# ET6801 register map
Vendor: ETMCU Inc.; File version: v0.0.1
CPU: CM7 r2p1, little endian, MPU, FPU, I-cache, D-cache, ITCM, DTCM, 4 interrupt priority bits
Registers are 32-bit, read-write, reset 0x0 unless marked. A register's access mark holds for its fields unless they carry their own. Offsets are from the block's base; [hi:lo] are bit positions; lines under a group give offsets from that group; {n}, {i} and the like mark numbered series.

## XBAR — Provide an overview of the purpose and functionality of the peripheral: xbar
Base 0x40020000
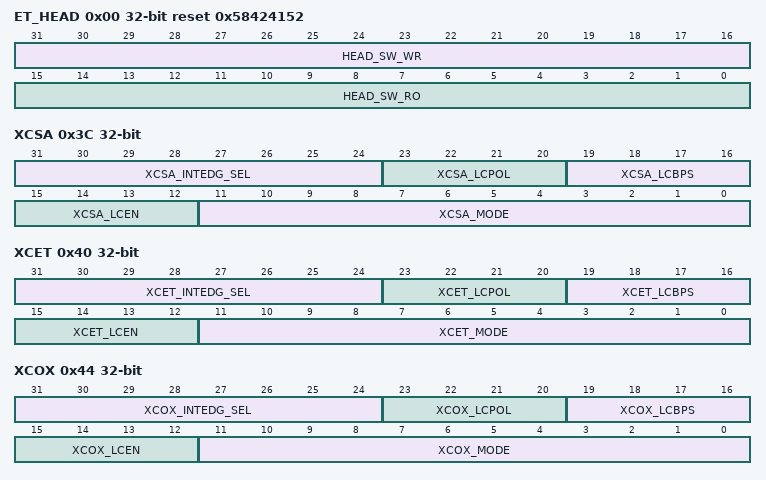
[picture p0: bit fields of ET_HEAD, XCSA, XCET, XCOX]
0x00 ET_HEAD reset 0x58424152
  [31:16] HEAD_SW_WR — 软件测试读写寄存器，硬件无访问
  [15:0] HEAD_SW_RO ro — 软件只读上报寄存器，硬件无访问，XBAR的ASICII 码表示
0x04 KEY
  [15:0] XBAR_KEY — XBAR配置key值，仅当配置为0x5a5a时可配置相关寄存器
0x08 FAULT_EN reset 0x7FFFFF
  [22:0] FAULT_EN — XBAR FAULT输入使能 0：对应fault不使能 1：对应fault使能
{0xC+8i} STM{i}ERG0_EN reset 0x7FFFFF (i=0..5)
  [22:0] STM{i}_ERGTRIG_0EN — STM{i}紧急触发源0使能 0：对应触发源不使能 1：对应触发源使能
{0x10+8i} STM{i}ERG1_EN reset 0x7FFFFF (i=0..5)
  [22:0] STM{i}_ERGTRIG_1EN — STM{i}紧急触发源1使能 0：对应触发源不使能 1：对应触发源使能
0x3C XCSA
  [31:24] XCSA_INTEDG_SEL — XBAR CLU2SAR 4个输出信号产生中断的沿类型选择 2'b01：上升沿 2'b10：下降沿 2'b11：上升沿和下降沿 其他：不取沿
  [23:20] XCSA_LCPOL — XBAR CLU2SAR输出4个bit对应的极性选择 0：不取反 1：取反
  [19:16] XCSA_LCBPS — XBAR CLU2SAR对应输出4个bit的CLU功能旁路使能，高有效，旁路后选择输出INPUTXBAR对应信号： CLU旁路输出bit0对应INPUTXBAR输出bit0 CLU旁路输出bit1对应INPUTXBAR输出bit4 CLU旁路输出bit2对应INPUTXBAR输出bit8 CLU旁路输出bit3对应INPUTXBAR输出bit12
  [15:12] XCSA_LCEN — XBAR CLU2SAR对应输出4个bit的输出使能： 0：输出低电平 1：输出高电平
  [11:0] XCSA_MODE — bit[2:0]：XBAR CLU2SAR输出bit0的8种逻辑选择 bit[5:3]：XBAR CLU2SAR输出bit1的8种逻辑选择 bit[8:6]：XBAR CLU2SAR输出bit2的8种逻辑选择 bit[11:9]：XBAR CLU2SAR输出bit3的8种逻辑选择
0x40 XCET
  [31:24] XCET_INTEDG_SEL — XBAR CLU2ETIMER 4个输出信号产生中断的沿类型选择 2'b01：上升沿 2'b10：下降沿 2'b11：上升沿和下降沿 其他：不取沿
  [23:20] XCET_LCPOL — XBAR CLU2ETIMER输出4个bit对应的极性选择 0：不取反 1：取反
  [19:16] XCET_LCBPS — XBAR CLU2ETIMER对应输出4个bit的CLU功能旁路使能，高有效，旁路后选择输出INPUTXBAR对应信号： CLU旁路输出bit0对应INPUTXBAR输出bit0 CLU旁路输出bit1对应INPUTXBAR输出bit4 CLU旁路输出bit2对应INPUTXBAR输出bit8 CLU旁路输出bit3对应INPUTXBAR输出bit12
  [15:12] XCET_LCEN — XBAR CLU2ETIMER对应输出4个bit的输出使能： 0：输出低电平 1：输出高电平
  [11:0] XCET_MODE — bit[2:0]：XBAR CLU2ETIMER输出bit0的8种逻辑选择 bit[5:3]：XBAR CLU2ETIMER输出bit1的8种逻辑选择 bit[8:6]：XBAR CLU2ETIMER输出bit2的8种逻辑选择 bit[11:9]：XBAR CLU2ETIMER输出bit3的8种逻辑选择
0x44 XCOX
  [31:24] XCOX_INTEDG_SEL — XBAR CLU2OUTXBAR 4个输出信号产生中断的沿类型选择 2'b01：上升沿 2'b10：下降沿 2'b11：上升沿和下降沿 其他：不取沿
  [23:20] XCOX_LCPOL — XBAR CLU2OUTXBAR输出4个bit对应的极性选择 0：不取反 1：取反
  [19:16] XCOX_LCBPS — XBAR CLU2OUTXBAR对应输出4个bit的CLU功能旁路使能，高有效，旁路后选择输出INPUTXBAR对应信号： CLU旁路输出bit0对应INPUTXBAR输出bit0 CLU旁路输出bit1对应INPUTXBAR输出bit4 CLU旁路输出bit2对应INPUTXBAR输出bit8 CLU旁路输出bit3对应INPUTXBAR输出bit12
  [15:12] XCOX_LCEN — XBAR CLU2OUTXBAR对应输出4个bit的输出使能： 0：输出低电平 1：输出高电平
  [11:0] XCOX_MODE — bit[2:0]：XBAR CLU2OUTXBAR输出bit0的8种逻辑选择 bit[5:3]：XBAR CLU2OUTXBAR输出bit1的8种逻辑选择 bit[8:6]：XBAR CLU2OUTXBAR输出bit2的8种逻辑选择 bit[11:9]：XBAR CLU2OUTXBAR输出bit3的8种逻辑选择
0x48 INXB_DSEL
  [31:0] INXB_DSEL — INPUTXBAR第0路到第15路输出信号处理选择： Bit[1:0]：INPUTXBAR第0路输出选择 2'd0：选择MUX后数据输出 2'd1：选择高电平锁存后数据输出 2'd2：选择上升沿输出 2'd3：选择下降沿输出 Bit[3:2]：INPUTXBAR第1路输出选择，选项同上 ... Bit[31:30]：INPUTXBAR第15路输出选择，选项同上
0x4C INXB_LATCLR
  [15:0] INXB_LAT_CLR — INPUTXBAR第0路到第15路输出信号锁存清除配置，自清0
0x50 INXB_OE
  [15:0] INXB_OE — INPUTXBAR第0路到第15路输出使能，高有效
0x54 INXB_OUTPOL
  [15:0] INXB_OUTPOL — INPUTXBAR第0路到第15路输出信号极性配置 0：不取反 1：取反
0x58 INXB_OUTDSEL reset 0xFFFF
  [15:0] INXB_OUTDSEL — INPUTXBAR第0路到第15路输出信号是否打拍手输出 0：不打拍 1：打拍
{0x5C+0xC*i} INXB_GRP[{i}] (i=0..15) group — CFG_INXB_GRP
  0x00 INXB_MUX0
    [31:0] INXB_15_0MUX — INPUTXBAR第N(0~15)路输出对应的第0到第15组MUX通道4选1配置
  0x04 INXB_MUX1
    [31:0] INXB_31_16MUX — INPUTXBAR第N(0~15)路输出对应的第16到第31组MUX通道4选1配置
  0x08 INXB_ENB
    [31:0] INXB_ENB — INPUTXBAR第N(0~15)路输出对应的第0到第31组MUX选择后信号ENB配置 0：不使能 1：使能
0x11C PFXB_DSEL
  [31:0] PFXB_DSEL — PWMXBAR第0路到第15路输出信号处理选择： Bit[1:0]：PWMXBAR第0路输出选择 2'd0：选择MUX后数据输出 2'd1：选择高电平锁存后数据输出 2'd2：选择上升沿输出 2'd3：选择下降沿输出 Bit[3:2]：PWMXBAR第1路输出选择，选项同上 ... Bit[21:20]：PWMXBAR第11路输出选择，选项同上
0x120 PFXB_LATCLR
  [15:0] PFXB_LAT_CLR — PWMXBAR第0路到第15路输出信号锁存清除配置，自清0
0x124 PFXB_OE
  [15:0] PFXB_OE — PWMXBAR第0路到第15路输出使能，高有效
0x128 PFXB_OUTPOL
  [15:0] PFXB_OUTPOL — PWMXBAR第0路到第15路输出信号极性配置 0：不取反 1：取反
0x12C PFXB_OUTDSEL reset 0xFFFF
  [15:0] PFXB_OUTDSEL — CLB_XBAR第0路到第15路输出信号是否打拍手输出 0：不打拍 1：打拍
{0x130+0x18*i} PFXB_GRP[{i}] (i=0..15) group — CFG_PFXB_GRP
  {0x0+4j} PFXB_MUX{j} (j=0..3)
    [31:0] PFXB_{16j+15}_{16j}MUX — PWMXBAR第N(0~11)路输出对应的第{16j}到第{16j+15}组MUX通道4选1配置
  0x10 PFXB_ENB0
    [31:0] PFXB_ENB — PWMXBAR第N(0~11)路输出对应的第0到第31组MUX选择后信号ENB配置 0：不使能 1：使能
  0x14 PFXB_ENB1
    [31:0] PFXB_ENB — PWMXBAR第N(0~11)路输出对应的第32到第63组MUX选择后信号ENB配置 0：不使能 1：使能
0x2B0 ETXB_DSEL
  [23:0] ETXB_DSEL — eTimer XBAR第0路到第11路输出信号处理选择： Bit[1:0]：eTimer XBAR第0路输出选择 2'd0：选择MUX后数据输出 2'd1：选择高电平锁存后数据输出 2'd2：选择上升沿输出 2'd3：选择下降沿输出 Bit[3:2]：eTimer XBAR第1路输出选择，选项同上 ... Bit[27:26]：eTimer XBAR第11路输出选择，选项同上
0x2B4 ETXB_LATCLR
  [11:0] ETXB_LAT_CLR — eTimer XBAR第0路到第11路输出信号锁存清除配置，自清0
0x2B8 ETXB_OE
  [11:0] ETXB_OE — eTimer XBAR第0路到第11路输出使能，高有效
0x2BC ETXB_OUTPOL
  [11:0] ETXB_OUTPOL — eTimer XBAR第0路到第11路输出信号极性配置 0：不取反 1：取反
0x2C0 ETXB_SW
  [11:0] ETXB_SW — eTimer XBAR软件配置的输入信号 Bit0：第0个软件通道配置 ... Bit13：第11个软件通道配置
0x2C4 ETXB_OUTDSEL reset 0xFFF
  [11:0] ETXB_OUTDSEL — eTimer_XBAR第0路到第11路输出信号是否打拍手输出 0：不打拍 1：打拍
{0x2C8+0xC*i} ETXB_GRP[{i}] (i=0..11) group — CFG_ETXB_GRP
  0x00 ETXB_MUX0
    [31:0] ETXB_15_0MUX — eTimer XBAR第N(0~13)路输出对应的第0到第15组MUX通道4选1配置
  0x04 ETXB_MUX1
    [31:0] ETXB_31_16MUX — eTimer XBAR第N(0~13)路输出对应的第16到第31组MUX通道4选1配置
  0x08 ETXB_ENB
    [31:0] ETXB_ENB — eTimer XBAR第N(0~13)路输出对应的第0到第31组MUX选择后信号ENB配置 0：不使能 1：使能
0x358 OPXB_DSEL
  [23:0] OPXB_DSEL — OUTPUTXBAR第0路到第11路输出信号处理选择： Bit[1:0]：OUTPUTXBAR第0路输出选择 根据 ：选择MUX异步处理后取上升沿沿展宽输出 Bit[3:2]：OUTPUTXBAR第1路输出选择，选项同上 ... Bit[27:26]：OUTPUTXBAR第11路输出选择，选项同上
0x35C OPXB_LATCLR
  [11:0] OPXB_LAT_CLR — OUTPUTXBAR第0路到第11路输出信号锁存清除配置，自清0
0x360 OPXB_OE
  [11:0] OPXB_OE — OUTPUTXBAR第0路到第11路输出使能，高有效
0x364 OPXB_OUTPOL
  [11:0] OPXB_OUTPOL — OUTPUTXBAR第0路到第11路输出信号极性配置 0：不取反 1：取反
0x368 OPXB_SW
  [11:0] OPXB_SW — OUTPUTXBAR软件配置的输入信号 Bit0：第0个软件通道配置 ... Bit13：第11个软件通道配置
0x36C OPXB_EXPEN
  [11:0] OPXB_EXP_EN — OUTPUTXBAR第0路到第11路电平扩展输出使能配置 根据 ：选择MUX异步处理后取上升沿沿展宽输出 展宽15个周期
0x370 OPXB_OEMOD
  [23:0] OPXB_OEMOD — bit[1:0]：OUTPUTXBAR第0路输出使能模式选择 2'd1：当选择信号中包含eTimer PWM信号时，对应输出管脚选择eTimer PWM oen作为输出使能，其他管脚固定输出有效 2'd2：固定输出三态 others：固定为输出有效 bit[3:2]：OUTPUTXBAR第1路输出使能模式选择 ... bit[27:26]：OUTPUTXBAR第11路输出使能模式选择
{0x374+0x18*i} OPXB_GRP[{i}] (i=0..11) group — CFG_OPXB_GRP
  {0x0+4j} OPXB_MUX{j} (j=0..3)
    [31:0] OPXB_{16j+15}_{16j}MUX — OUTPUTXBAR第N(0~11)路输出对应的第{16j}到第{16j+15}组MUX通道4选1配置
  0x10 OPXB_ENB0
    [31:0] OPXB_ENB — OUTPUTXBAR第N(0~11)路输出对应的第0到第31组MUX选择后信号ENB配置 0：不使能 1：使能
  0x14 OPXB_ENB1
    [31:0] OPXB_ENB — OUTPUTXBAR第N(0~11)路输出对应的第32到第63组MUX选择后信号ENB配置 0：不使能 1：使能
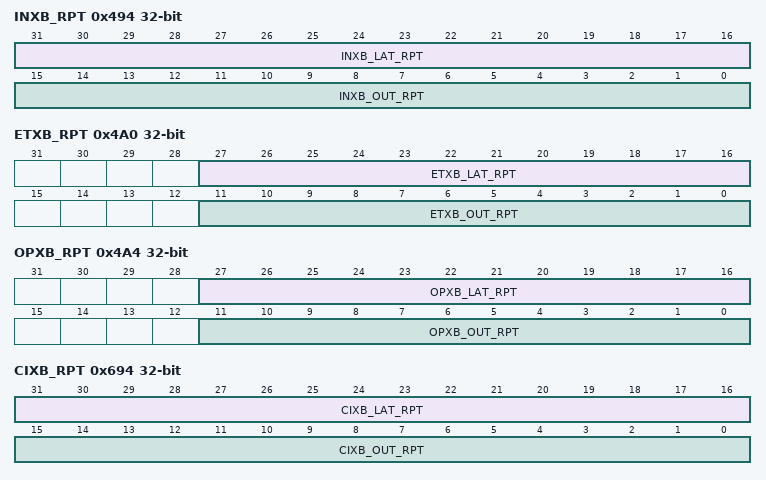
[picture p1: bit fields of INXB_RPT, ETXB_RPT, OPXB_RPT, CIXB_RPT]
0x494 INXB_RPT ro
  [31:16] INXB_LAT_RPT — INPUTXBAR锁存状态上报
  [15:0] INXB_OUT_RPT — INPUTXBAR实时输出状态上报
0x498 PFXB_RPT0 ro
  [15:0] PFXB_OUT_RPT — PWMXBAR实时输出状态上报
0x49C PFXB_RPT1 ro
  [15:0] PFXB_LAT_RPT — PWMXBAR锁存状态上报
0x4A0 ETXB_RPT ro
  [27:16] ETXB_LAT_RPT — eTimer XBAR锁存状态上报
  [11:0] ETXB_OUT_RPT — eTimer XBAR实时输出状态上报
0x4A4 OPXB_RPT ro
  [27:16] OPXB_LAT_RPT — OUTPUTXBAR锁存状态上报
  [11:0] OPXB_OUT_RPT — OUTPUTXBAR实时输出状态上报
0x4A8 CLU_INT_EN
  [11:0] CLU_INT_EN — 1表示使能CLU逻辑中断;0 取消使能 每一bit代表： bit[12]:xcox3 bit[11]:xcox2 bit[10]:xcox1 bit[9]:xcox0 bit[7]:xct3 bit[6]:xcet2 bit[5]:xcet1 bit[4]:xcet0 bit[3]:xcsa3 bit[2]:xcsa2 bit[1]:xcsa1 bit[0]:xcsa0
0x4AC CLU_INT_MASK
  [11:0] CLU_INT_MASK — 1表示屏蔽CLU逻辑中断;0 取消屏蔽 每一bit代表同CFG_CLU_INT_EN
0x4B0 CLU_INT_FORCE_IND
  [11:0] CLU_INT_FORCE_IND — 1表示强制产生相应的测试中断，硬件自清零 每一bit代表同CFG_CLU_INT_EN
0x4B4 CLU_INT_CLR
  [11:0] CLU_INT_CLR — 1表示清除相应的中断状态，硬件自清零 每一bit代表同CFG_CLU_INT_EN
0x4B8 CLU_INT_RAW_RPT ro
  [11:0] CLU_INT_RAW_RPT — 中断MASK前RAW 中断状态上报 每一bit代表同CFG_CLU_INT_EN
0x4BC CLU_INT_STATUS_RPT ro
  [11:0] CLU_INT_STATUS_RPT — 中断MASK后中断状态上报 每一bit代表同CFG_CLU_INT_EN
0x4C0 INXB_INT_EN
  [4:0] INXB_INT_EN — 1表示使能INXB逻辑中断;0 取消使能 每一bit代表： bit[4]:inxb_dout[15] bit[3]:inxb_dout[14] bit[2]:inxb_dout[13] bit[1]:inxb_dout[12]， bit[0]:inxb_dout[11],inputxbar输出的第11bit
0x4C4 INXB_INT_MASK
  [4:0] INXB_INT_MASK — 1表示屏蔽INXB逻辑中断;0 取消屏蔽 每一bit代表同CFG_INXB_INT_EN
0x4C8 INXB_INT_FORCE_IND
  [4:0] INXB_INT_FORCE_IND — 1表示强制产生相应的测试中断，硬件自清零 每一bit代表同CFG_INXB_INT_EN
0x4CC INXB_INT_CLR
  [4:0] INXB_INT_CLR — 1表示清除相应的中断状态，硬件自清零 每一bit代表同CFG_INXB_INT_EN
0x4D0 INXB_INT_RAW_RPT ro
  [4:0] INXB_INT_RAW_RPT — 中断MASK前RAW 中断状态上报 每一bit代表同CFG_INXB_INT_EN
0x4D4 INXB_INT_STATUS_RPT ro
  [4:0] INXB_INT_STATUS_RPT — 中断MASK后中断状态上报 每一bit代表同CFG_INXB_INT_EN
0x4D8 CIXB_DSEL
  [31:0] CIXB_DSEL — CLB_INPUTXBAR第0路到第15路输出信号处理选择： Bit[1:0]：CLB_INPUTXBAR第0路输出选择 2'd0：选择MUX后数据输出 2'd1：选择高电平锁存后数据输出 2'd2：选择上升沿输出 2'd3：选择下降沿输出 Bit[3:2]：CLB_INPUTXBAR第1路输出选择，选项同上 ... Bit[31:30]：CLB_INPUTXBAR第15路输出选择，选项同上
0x4DC CIXB_LATCLR
  [15:0] CIXB_LAT_CLR — CLB_INPUTXBAR第0路到第15路输出信号锁存清除配置，自清0
0x4E0 CIXB_OE
  [15:0] CIXB_OE — CLB_INPUTXBAR第0路到第15路输出使能，高有效
0x4E4 CIXB_OUTPOL
  [15:0] CIXB_OUTPOL — CLB_INPUTXBAR第0路到第15路输出信号极性配置 0：不取反 1：取反
0x4E8 CIXB_OUTDSEL reset 0xFFFF
  [15:0] CIXB_OUTDSEL — CLB_INPUTXBAR第0路到第15路输出信号是否打拍手输出 0：不打拍 1：打拍
{0x4EC+0xC*i} CIXB_GRP[{i}] (i=0..15) group — CFG_CIXB_GRP
  0x00 CIXB_MUX0
    [31:0] CIXB_15_0MUX — CLB_INPUTXBAR第N(0~15)路输出对应的第0到第15组MUX通道4选1配置
  0x04 CIXB_MUX1
    [31:0] CIXB_31_16MUX — CLB_INPUTXBAR第N(0~15)路输出对应的第16到第19组MUX通道4选1配置
  0x08 CIXB_ENB
    [31:0] CIXB_ENB — CLB_INPUTXBAR第N(0~15)路输出对应的第0到第31组MUX选择后信号ENB配置 0：不使能 1：使能
0x5AC CBXB_DSEL
  [15:0] CBXB_DSEL — CLB_XBAR第0路到第7路输出信号处理选择： Bit[1:0]：CLB_XBAR第0路输出选择 2'd0：选择MUX后数据输出 2'd1：选择高电平锁存后数据输出 2'd2：选择上升沿输出 2'd3：选择下降沿输出 Bit[3:2]：CLB_XBAR第1路输出选择，选项同上 ... Bit[15:14]：CLB_XBAR第7路输出选择，选项同上
0x5B0 CBXB_LATCLR
  [7:0] CBXB_LAT_CLR — CLB_XBAR第0路到第7路输出信号锁存清除配置，自清0
0x5B4 CBXB_OE
  [7:0] CBXB_OE — CLB_XBAR第0路到第7路输出使能，高有效
0x5B8 CBXB_OUTPOL
  [7:0] CBXB_OUTPOL — CLB_XBAR第0路到第7路输出信号极性配置 0：不取反 1：取反
0x5BC CBXB_OUTDSEL reset 0xFF
  [7:0] CBXB_OUTDSEL — CLB_XBAR第0路到第7路输出信号是否打拍手输出 0：不打拍 1：打拍
{0x5C0+0xC*i} CBXB_GRP[{i}] (i=0..7) group — CFG_CBXB_GRP
  0x00 CBXB_MUX0
    [31:0] CBXB_15_0MUX — CLB_XBAR第N(0~7)路输出对应的第0到第15组MUX通道4选1配置
  0x04 CBXB_MUX1
    [31:0] CBXB_31_16MUX — CLB_XBAR第N(0~7)路输出对应的第16到第31组MUX通道4选1配置
  0x08 CBXB_ENB
    [31:0] CBXB_ENB — CLB_XBAR第N(0~7)路输出对应的第0到第31组MUX选择后信号ENB配置 0：不使能 1：使能
0x620 COXB_DSEL
  [15:0] COXB_DSEL — OUTPUTXBAR第0路到第7路输出信号处理选择： Bit[1:0]：OUTPUTXBAR第0路输出选择 根据 ：选择MUX异步处理后取上升沿沿展宽输出 Bit[3:2]：OUTPUTXBAR第1路输出选择，选项同上 ... Bit[15:14]：OUTPUTXBAR第7路输出选择，选项同上
0x624 COXB_LATCLR
  [7:0] COXB_LAT_CLR — OUTPUTXBAR第0路到第7路输出信号锁存清除配置，自清0
0x628 COXB_OE
  [7:0] COXB_OE — OUTPUTXBAR第0路到第7路输出使能，高有效
0x62C COXB_OUTPOL
  [7:0] COXB_OUTPOL — OUTPUTXBAR第0路到第7路输出信号极性配置 0：不取反 1：取反
0x630 COXB_EXPEN
  [7:0] COXB_EXP_EN — OUTPUTXBAR第0路到第7路电平扩展输出使能配置 根据 ：选择MUX异步处理后取上升沿沿展宽输出 展宽15个周期
{0x634+0xC*i} COXB_GRP[{i}] (i=0..7) group — CFG_COXB_GRP
  0x00 COXB_MUX0
    [31:0] COXB_15_0MUX — OUTPUTXBAR第N(0~7)路输出对应的第0到第15组MUX通道4选1配置
  0x04 COXB_MUX1
    [31:0] COXB_31_16MUX — OUTPUTXBAR第N(0~7)路输出对应的第16到第31组MUX通道4选1配置
  0x08 COXB_ENB
    [31:0] COXB_ENB — OUTPUTXBAR第N(0~7)路输出对应的第0到第31组MUX选择后信号ENB配置 0：不使能 1：使能
0x694 CIXB_RPT ro
  [31:16] CIXB_LAT_RPT — CLB_INPUTXBAR锁存状态上报
  [15:0] CIXB_OUT_RPT — CLB_INPUTXBAR实时输出状态上报
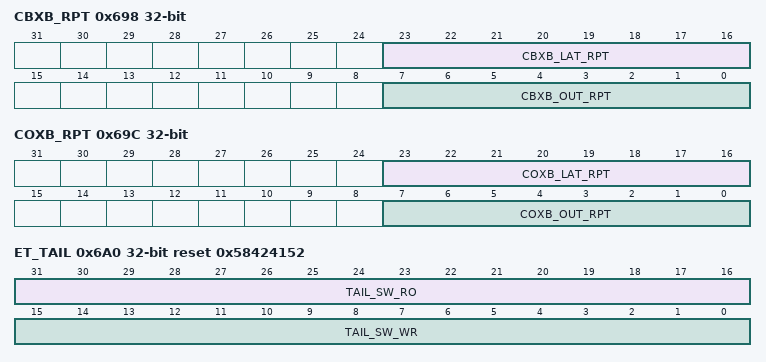
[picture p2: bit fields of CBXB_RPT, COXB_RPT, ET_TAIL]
0x698 CBXB_RPT ro
  [23:16] CBXB_LAT_RPT — CLB_XBAR锁存状态上报
  [7:0] CBXB_OUT_RPT — CLB_XBAR实时输出状态上报
0x69C COXB_RPT ro
  [23:16] COXB_LAT_RPT — CLB_OUTPUTXBAR锁存状态上报
  [7:0] COXB_OUT_RPT — CLB_OUTPUTXBAR实时输出状态上报
0x6A0 ET_TAIL reset 0x58424152
  [31:16] TAIL_SW_RO ro — 软件只读硬件上报寄存器
  [15:0] TAIL_SW_WR — 软件测试读写寄存器，硬件无访问
